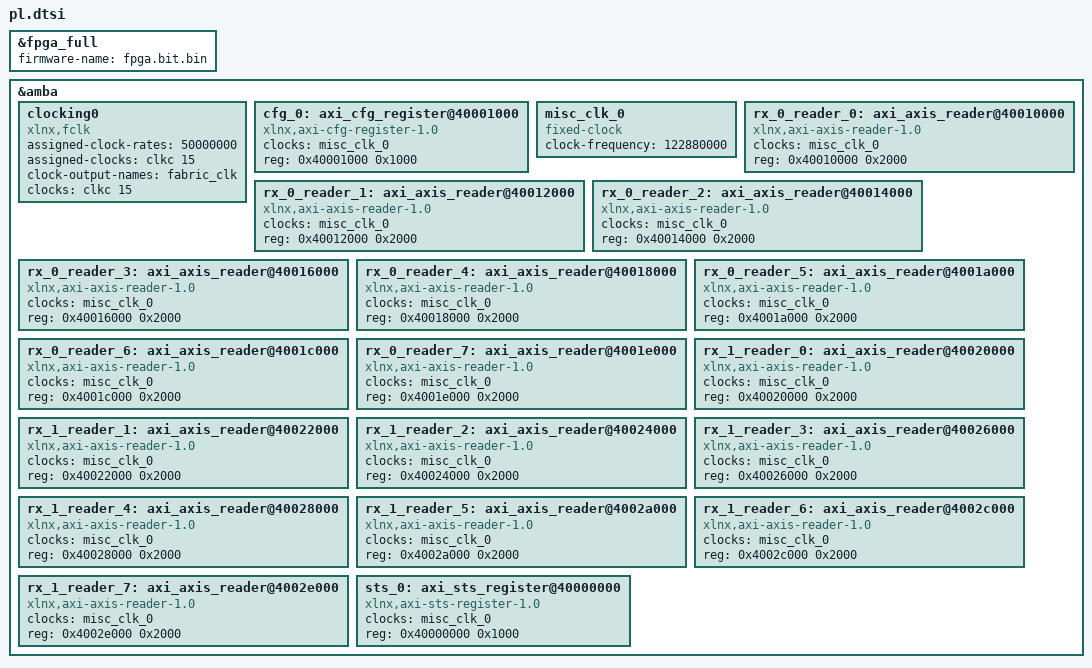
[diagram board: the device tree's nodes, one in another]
/*
 * CAUTION: This file is automatically generated by Xilinx.
 * Version:  
 * Today is: Thu May  4 13:39:38 2023
 */


/dts-v1/;
/plugin/;
/ {
	fragment@0 {
		target = <&fpga_full>;
		overlay0: __overlay__ {
			//#address-cells = <2>;
			//#size-cells = <2>;
			firmware-name = "fpga.bit.bin";
		};
	};
	fragment@1 {
		target = <&amba>;
		overlay1: __overlay__ {
			clocking0: clocking0 {
				#clock-cells = <0>;
				assigned-clock-rates = <50000000>;
				assigned-clocks = <&clkc 15>;
				clock-output-names = "fabric_clk";
				clocks = <&clkc 15>;
				compatible = "xlnx,fclk";
			};
		};
	};
	fragment@2 {
		target = <&amba>;
		overlay2: __overlay__ {
			//#address-cells = <1>;
			//#size-cells = <1>;
			cfg_0: axi_cfg_register@40001000 {
				clock-names = "aclk";
				clocks = <&misc_clk_0>;
				compatible = "xlnx,axi-cfg-register-1.0";
				reg = <0x40001000 0x1000>;
			};
			misc_clk_0: misc_clk_0 {
				#clock-cells = <0>;
				clock-frequency = <122880000>;
				compatible = "fixed-clock";
			};
			rx_0_reader_0: axi_axis_reader@40010000 {
				clock-names = "aclk";
				clocks = <&misc_clk_0>;
				compatible = "xlnx,axi-axis-reader-1.0";
				reg = <0x40010000 0x2000>;
			};
			rx_0_reader_1: axi_axis_reader@40012000 {
				clock-names = "aclk";
				clocks = <&misc_clk_0>;
				compatible = "xlnx,axi-axis-reader-1.0";
				reg = <0x40012000 0x2000>;
			};
			rx_0_reader_2: axi_axis_reader@40014000 {
				clock-names = "aclk";
				clocks = <&misc_clk_0>;
				compatible = "xlnx,axi-axis-reader-1.0";
				reg = <0x40014000 0x2000>;
			};
			rx_0_reader_3: axi_axis_reader@40016000 {
				clock-names = "aclk";
				clocks = <&misc_clk_0>;
				compatible = "xlnx,axi-axis-reader-1.0";
				reg = <0x40016000 0x2000>;
			};
			rx_0_reader_4: axi_axis_reader@40018000 {
				clock-names = "aclk";
				clocks = <&misc_clk_0>;
				compatible = "xlnx,axi-axis-reader-1.0";
				reg = <0x40018000 0x2000>;
			};
			rx_0_reader_5: axi_axis_reader@4001a000 {
				clock-names = "aclk";
				clocks = <&misc_clk_0>;
				compatible = "xlnx,axi-axis-reader-1.0";
				reg = <0x4001a000 0x2000>;
			};
			rx_0_reader_6: axi_axis_reader@4001c000 {
				clock-names = "aclk";
				clocks = <&misc_clk_0>;
				compatible = "xlnx,axi-axis-reader-1.0";
				reg = <0x4001c000 0x2000>;
			};
			rx_0_reader_7: axi_axis_reader@4001e000 {
				clock-names = "aclk";
				clocks = <&misc_clk_0>;
				compatible = "xlnx,axi-axis-reader-1.0";
				reg = <0x4001e000 0x2000>;
			};
			rx_1_reader_0: axi_axis_reader@40020000 {
				clock-names = "aclk";
				clocks = <&misc_clk_0>;
				compatible = "xlnx,axi-axis-reader-1.0";
				reg = <0x40020000 0x2000>;
			};
			rx_1_reader_1: axi_axis_reader@40022000 {
				clock-names = "aclk";
				clocks = <&misc_clk_0>;
				compatible = "xlnx,axi-axis-reader-1.0";
				reg = <0x40022000 0x2000>;
			};
			rx_1_reader_2: axi_axis_reader@40024000 {
				clock-names = "aclk";
				clocks = <&misc_clk_0>;
				compatible = "xlnx,axi-axis-reader-1.0";
				reg = <0x40024000 0x2000>;
			};
			rx_1_reader_3: axi_axis_reader@40026000 {
				clock-names = "aclk";
				clocks = <&misc_clk_0>;
				compatible = "xlnx,axi-axis-reader-1.0";
				reg = <0x40026000 0x2000>;
			};
			rx_1_reader_4: axi_axis_reader@40028000 {
				clock-names = "aclk";
				clocks = <&misc_clk_0>;
				compatible = "xlnx,axi-axis-reader-1.0";
				reg = <0x40028000 0x2000>;
			};
			rx_1_reader_5: axi_axis_reader@4002a000 {
				clock-names = "aclk";
				clocks = <&misc_clk_0>;
				compatible = "xlnx,axi-axis-reader-1.0";
				reg = <0x4002a000 0x2000>;
			};
			rx_1_reader_6: axi_axis_reader@4002c000 {
				clock-names = "aclk";
				clocks = <&misc_clk_0>;
				compatible = "xlnx,axi-axis-reader-1.0";
				reg = <0x4002c000 0x2000>;
			};
			rx_1_reader_7: axi_axis_reader@4002e000 {
				clock-names = "aclk";
				clocks = <&misc_clk_0>;
				compatible = "xlnx,axi-axis-reader-1.0";
				reg = <0x4002e000 0x2000>;
			};
			sts_0: axi_sts_register@40000000 {
				clock-names = "aclk";
				clocks = <&misc_clk_0>;
				compatible = "xlnx,axi-sts-register-1.0";
				reg = <0x40000000 0x1000>;
			};
		};
	};
};
